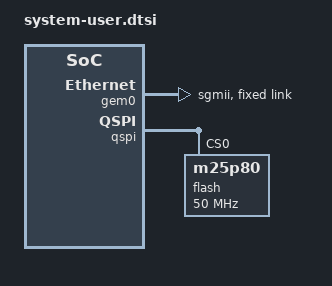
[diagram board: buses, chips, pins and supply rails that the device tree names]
/ {
	chosen {
		bootargs = " earlycon console=ttyPS0,115200 clk_ignore_unused root=/dev/ram0 rw";
		stdout-path = "serial0:115200n8";
	};
};
/ {
	axi_stream_dma_0@b0000000 {
		compatible = "axi_stream_dma";
		reg = <0x0 0xb0000000 0x0 0x10000>;
		interrupts = <0 89 4>;
		interrupt-parent = <&gic>;
	};
};
&gem0 {
	local-mac-address = [08 00 56 00 00 00];
	phy-mode = "sgmii";
	fixed-link {
		speed = <1000>;
		full-duplex;
	};
};
&sdhci1 {
	disable-wp;
	no-1-8-v;
};
&qspi {
	num-cs = <2>;
	is-dual = <1>;
	flash@0 {
		compatible = "m25p80", "jedec,spi-nor"; /* dual MT25QU02G (2Gbit) */
		#address-cells = <1>;
		#size-cells = <1>;
		reg = <0>, <1>;
		parallel-memories = /bits/ 64 <0x10000000 0x10000000>; /* 256MB */
		spi-tx-bus-width = <4>;
		spi-rx-bus-width = <4>;
		spi-max-frequency = <50000000>;
	};
};
